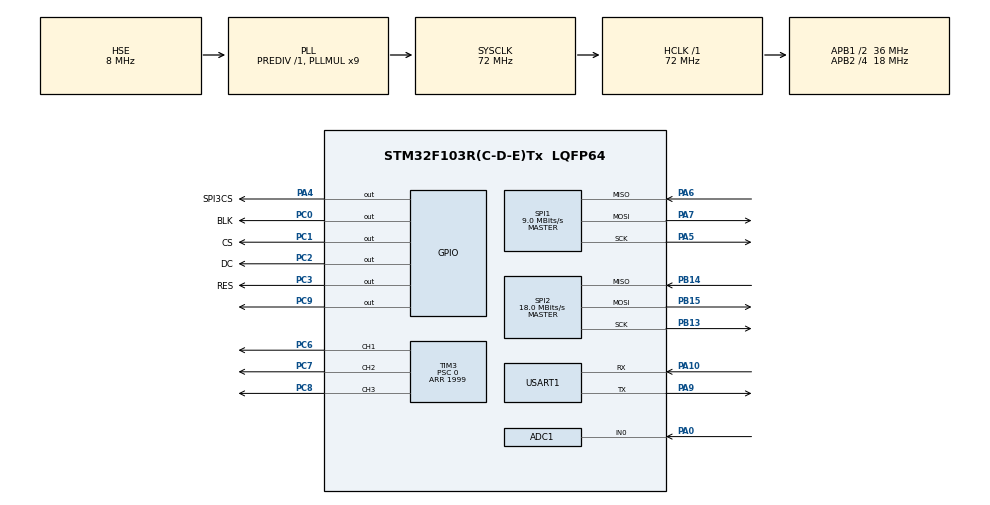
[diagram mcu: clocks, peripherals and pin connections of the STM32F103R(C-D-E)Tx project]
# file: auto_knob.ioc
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ADC1.Channel-0\#ChannelRegularConversion=ADC_CHANNEL_0
ADC1.ContinuousConvMode=ENABLE
ADC1.NbrOfConversion=1
ADC1.NbrOfConversionFlag=1
ADC1.Rank-0\#ChannelRegularConversion=1
ADC1.SamplingTime-0\#ChannelRegularConversion=ADC_SAMPLETIME_41CYCLES_5
ADC1.master=1
Dma.ADC1.0.Direction=DMA_PERIPH_TO_MEMORY
Dma.ADC1.0.Instance=DMA1_Channel1
Dma.ADC1.0.MemDataAlignment=DMA_MDATAALIGN_HALFWORD
Dma.ADC1.0.MemInc=DMA_MINC_ENABLE
Dma.ADC1.0.Mode=DMA_CIRCULAR
Dma.ADC1.0.PeriphDataAlignment=DMA_PDATAALIGN_HALFWORD
Dma.ADC1.0.PeriphInc=DMA_PINC_DISABLE
Dma.ADC1.0.Priority=DMA_PRIORITY_LOW
Dma.Request0=ADC1
Dma.Request1=USART1_RX
Dma.USART1_RX.1.Direction=DMA_PERIPH_TO_MEMORY
Dma.USART1_RX.1.Instance=DMA1_Channel5
Dma.USART1_RX.1.MemDataAlignment=DMA_MDATAALIGN_BYTE
Dma.USART1_RX.1.MemInc=DMA_MINC_ENABLE
Dma.USART1_RX.1.Mode=DMA_NORMAL
Dma.USART1_RX.1.PeriphDataAlignment=DMA_PDATAALIGN_BYTE
Dma.USART1_RX.1.PeriphInc=DMA_PINC_DISABLE
Dma.USART1_RX.1.Priority=DMA_PRIORITY_LOW
Mcu.Family=STM32F1
Mcu.Name=STM32F103R(C-D-E)Tx
Mcu.Package=LQFP64
NVIC.DMA1_Channel1_IRQn=true\:0\:0\:false\:false\:true\:false\:true\:true
NVIC.DMA1_Channel5_IRQn=true\:0\:0\:false\:false\:true\:false\:true\:true
NVIC.PriorityGroup=NVIC_PRIORITYGROUP_4
NVIC.TIM2_IRQn=true\:0\:0\:false\:false\:true\:true\:true\:true
NVIC.USART1_IRQn=true\:0\:0\:false\:false\:true\:true\:true\:true
PA0-WKUP.Signal=ADCx_IN0
PA10.Mode=Asynchronous
PA10.Signal=USART1_RX
PA4.GPIO_Label=SPI3CS
PA4.Signal=GPIO_Output
PA5.Mode=Full_Duplex_Master
PA5.Signal=SPI1_SCK
PA6.Mode=Full_Duplex_Master
PA6.Signal=SPI1_MISO
PA7.Mode=Full_Duplex_Master
PA7.Signal=SPI1_MOSI
PA9.Mode=Asynchronous
PA9.Signal=USART1_TX
PB13.Mode=Full_Duplex_Master
PB13.Signal=SPI2_SCK
PB14.Mode=Full_Duplex_Master
PB14.Signal=SPI2_MISO
PB15.Mode=Full_Duplex_Master
PB15.Signal=SPI2_MOSI
PC0.GPIO_Label=BLK
PC0.Signal=GPIO_Output
PC1.GPIO_Label=CS
PC1.Signal=GPIO_Output
PC2.GPIO_Label=DC
PC2.Signal=GPIO_Output
PC3.GPIO_Label=RES
PC3.Signal=GPIO_Output
PC6.Signal=S_TIM3_CH1
PC7.Signal=S_TIM3_CH2
PC8.Signal=S_TIM3_CH3
PC9.Signal=GPIO_Output
PD0-OSC_IN.Mode=HSE-External-Oscillator
PD0-OSC_IN.Signal=RCC_OSC_IN
PD1-OSC_OUT.Mode=HSE-External-Oscillator
PD1-OSC_OUT.Signal=RCC_OSC_OUT
ProjectManager.HeapSize=0x200
ProjectManager.StackSize=0x400
ProjectManager.TargetToolchain=MDK-ARM V5.32
RCC.ADCPresc=RCC_ADCPCLK2_DIV8
RCC.AHBFreq_Value=72000000
RCC.APB1CLKDivider=RCC_HCLK_DIV2
RCC.APB1Freq_Value=36000000
RCC.APB1TimFreq_Value=72000000
RCC.APB2CLKDivider=RCC_HCLK_DIV4
RCC.APB2Freq_Value=18000000
RCC.APB2TimFreq_Value=36000000
RCC.HCLKFreq_Value=72000000
RCC.PLLMUL=RCC_PLL_MUL9
RCC.PLLSourceVirtual=RCC_PLLSOURCE_HSE
RCC.SYSCLKFreq_VALUE=72000000
RCC.SYSCLKSource=RCC_SYSCLKSOURCE_PLLCLK
RCC.USBFreq_Value=72000000
SH.ADCx_IN0.0=ADC1_IN0,IN0
SH.S_TIM3_CH1.0=TIM3_CH1,PWM Generation1 CH1
SH.S_TIM3_CH2.0=TIM3_CH2,PWM Generation2 CH2
SH.S_TIM3_CH3.0=TIM3_CH3,PWM Generation3 CH3
SPI1.BaudRatePrescaler=SPI_BAUDRATEPRESCALER_2
SPI1.CalculateBaudRate=9.0 MBits/s
SPI1.Direction=SPI_DIRECTION_2LINES
SPI1.Mode=SPI_MODE_MASTER
SPI1.VirtualType=VM_MASTER
SPI2.BaudRatePrescaler=SPI_BAUDRATEPRESCALER_2
SPI2.CLKPhase=SPI_PHASE_2EDGE
SPI2.CalculateBaudRate=18.0 MBits/s
SPI2.DataSize=SPI_DATASIZE_16BIT
SPI2.Direction=SPI_DIRECTION_2LINES
SPI2.Mode=SPI_MODE_MASTER
SPI2.VirtualType=VM_MASTER
TIM2.Period=999
TIM2.Prescaler=72
TIM3.Channel-PWM\ Generation1\ CH1=TIM_CHANNEL_1
TIM3.Channel-PWM\ Generation2\ CH2=TIM_CHANNEL_2
TIM3.Channel-PWM\ Generation3\ CH3=TIM_CHANNEL_3
TIM3.Period=1999
TIM3.Prescaler=0
USART1.VirtualMode=VM_ASYNC
VP_SYS_VS_ND.Mode=No_Debug
VP_TIM2_VS_ClockSourceINT.Mode=Internal
board=custom

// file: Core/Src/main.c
/* USER CODE BEGIN Header */
/**
 ******************************************************************************
 * @file           : main.c
 * @brief          : Main program body
 ******************************************************************************
 * @attention
 *
 * Copyright (c) 2023 STMicroelectronics.
 * All rights reserved.
 *
 * This software is licensed under terms that can be found in the LICENSE file
 * in the root directory of this software component.
 * If no LICENSE file comes with this software, it is provided AS-IS.
 *
 ******************************************************************************
 */
/* USER CODE END Header */
#include "main.h"
#include "adc.h"
#include "dma.h"
#include "spi.h"
#include "tim.h"
#include "usart.h"
#include "gpio.h"

/* USER CODE BEGIN Includes */
#include "knob.h"
/* USER CODE END Includes */

void SystemClock_Config(void);

int main(void)
{

    /* MCU Configuration--------------------------------------------------------*/

    /* Reset of all peripherals, Initializes the Flash interface and the Systick. */
    HAL_Init();

    /* Configure the system clock */
    SystemClock_Config();

    /* Initialize all configured peripherals */
    MX_GPIO_Init();
    MX_DMA_Init();
    MX_SPI1_Init();
    MX_ADC1_Init();
    MX_TIM2_Init();
    MX_TIM3_Init();
    MX_USART1_UART_Init();
    MX_SPI2_Init();
    /* USER CODE BEGIN 2 */

    Knob_Init();

    /* USER CODE END 2 */

    /* Infinite loop */
    /* USER CODE BEGIN WHILE */
    uint32_t count = 0;
    while (1)
    {
        /* USER CODE END WHILE */

        /* USER CODE BEGIN 3 */
        u1_printf("%f,%f\n", Motor_Current_Angle, Motor_Current_Speed);
        Knob_Draw();
    }
    /* USER CODE END 3 */
}

void SystemClock_Config(void)
{
    RCC_OscInitTypeDef RCC_OscInitStruct = {0};
    RCC_ClkInitTypeDef RCC_ClkInitStruct = {0};
    RCC_PeriphCLKInitTypeDef PeriphClkInit = {0};

    /** Initializes the RCC Oscillators according to the specified parameters
     * in the RCC_OscInitTypeDef structure.
     */
    RCC_OscInitStruct.OscillatorType = RCC_OSCILLATORTYPE_HSE;
    RCC_OscInitStruct.HSEState = RCC_HSE_ON;
    RCC_OscInitStruct.HSEPredivValue = RCC_HSE_PREDIV_DIV1;
    RCC_OscInitStruct.HSIState = RCC_HSI_ON;
    RCC_OscInitStruct.PLL.PLLState = RCC_PLL_ON;
    RCC_OscInitStruct.PLL.PLLSource = RCC_PLLSOURCE_HSE;
    RCC_OscInitStruct.PLL.PLLMUL = RCC_PLL_MUL9;
    if (HAL_RCC_OscConfig(&RCC_OscInitStruct) != HAL_OK)
    {
        Error_Handler();
    }

    /** Initializes the CPU, AHB and APB buses clocks
     */
    RCC_ClkInitStruct.ClockType = RCC_CLOCKTYPE_HCLK | RCC_CLOCKTYPE_SYSCLK | RCC_CLOCKTYPE_PCLK1 | RCC_CLOCKTYPE_PCLK2;
    RCC_ClkInitStruct.SYSCLKSource = RCC_SYSCLKSOURCE_PLLCLK;
    RCC_ClkInitStruct.AHBCLKDivider = RCC_SYSCLK_DIV1;
    RCC_ClkInitStruct.APB1CLKDivider = RCC_HCLK_DIV2;
    RCC_ClkInitStruct.APB2CLKDivider = RCC_HCLK_DIV4;

    if (HAL_RCC_ClockConfig(&RCC_ClkInitStruct, FLASH_LATENCY_2) != HAL_OK)
    {
        Error_Handler();
    }
    PeriphClkInit.PeriphClockSelection = RCC_PERIPHCLK_ADC;
    PeriphClkInit.AdcClockSelection = RCC_ADCPCLK2_DIV8;
    if (HAL_RCCEx_PeriphCLKConfig(&PeriphClkInit) != HAL_OK)
    {
        Error_Handler();
    }
}

/* USER CODE BEGIN 4 */
void HAL_TIM_PeriodElapsedCallback(TIM_HandleTypeDef *htim)
{
    if (htim->Instance == TIM2)
    {
        Knob_TIM();
        Motor_TIM();
    }
}

void HAL_UARTEx_RxEventCallback(UART_HandleTypeDef *huart, uint16_t Size)
{
    if (huart->Instance == USART1)
    {
        Knob_UART();
    }
}
/* USER CODE END 4 */

void Error_Handler(void)
{
    __disable_irq();
    while (1)
    {
    }
}
